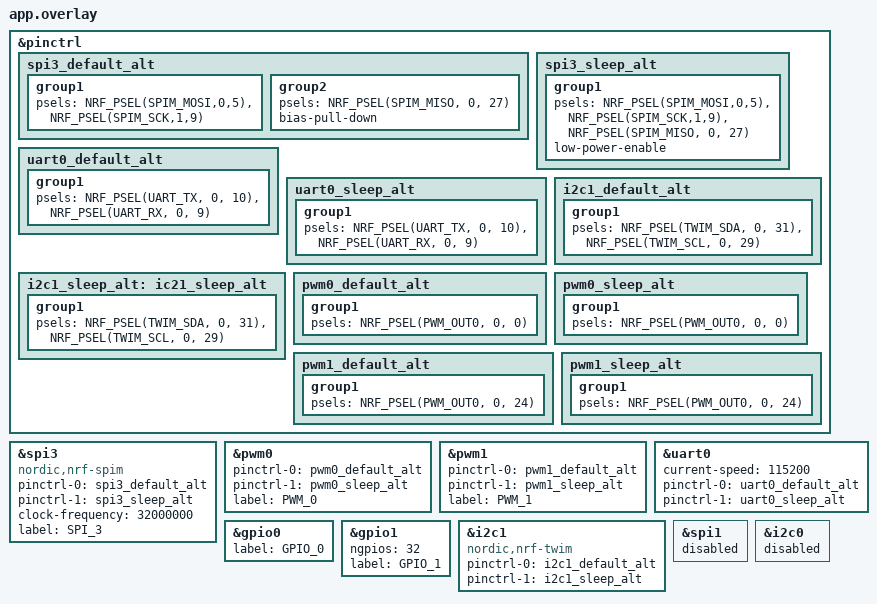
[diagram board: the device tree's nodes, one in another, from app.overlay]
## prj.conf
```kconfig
# Incresed stack due to settings API usage
CONFIG_SYSTEM_WORKQUEUE_STACK_SIZE=2048
CONFIG_MAIN_STACK_SIZE=4096


CONFIG_BT=y
CONFIG_BT_DEBUG_LOG=y
# Security manager protocol support for pairing
CONFIG_BT_SMP=y
# used to sign authenticated data
CONFIG_BT_SIGNING=y
# select peripheral role
CONFIG_BT_PERIPHERAL=n

# enable GATT device information service
CONFIG_BT_DIS=n
# number of buffers available for GATT writing
CONFIG_BT_ATT_PREPARE_COUNT=5


# enables local privacy feature support (Random MAC)
CONFIG_BT_PRIVACY=n
# name that appears when browsing
CONFIG_BT_DEVICE_NAME="DublinMaker"

# 0x4c0 = generic control device = 1216
CONFIG_BT_DEVICE_APPEARANCE=1216
# disable updating of device name to prevent use of generic name
# disable run-time changing of device name
CONFIG_BT_DEVICE_NAME_DYNAMIC=n
# CONFIG_BT_DEVICE_NAME_MAX=65
CONFIG_BT_OBSERVER=y
CONFIG_BT_KEYS_OVERWRITE_OLDEST=y

CONFIG_BT_RX_STACK_SIZE=1280
CONFIG_BT_CTLR_DUP_FILTER_LEN=0
CONFIG_BT_OBSERVER=y
CONFIG_BT_BROADCASTER=y
CONFIG_BT_PHY_UPDATE=n
CONFIG_BT_DATA_LEN_UPDATE=n

CONFIG_BT_MESH=y
CONFIG_BT_MESH_RELAY=y
CONFIG_BT_MESH_SEG_BUFS=10
CONFIG_BT_MESH_SUBNET_COUNT=1
CONFIG_BT_MESH_APP_KEY_COUNT=2
CONFIG_BT_MESH_MODEL_GROUP_COUNT=2
CONFIG_BT_MESH_ADV_BUF_COUNT=3
CONFIG_BT_MESH_LOOPBACK_BUFS=8
CONFIG_BT_MESH_PB_ADV=n
CONFIG_BT_MESH_CFG_CLI=y
CONFIG_BT_MESH_BEACON_ENABLED=n
CONFIG_BT_MESH_RPL_STORE_TIMEOUT=600
CONFIG_BT_MESH_DEBUG=y

CONFIG_BT_SETTINGS=n
CONFIG_FLASH=y
CONFIG_FLASH_PAGE_LAYOUT=y
CONFIG_FLASH_MAP=y
CONFIG_NVS=y
CONFIG_SETTINGS=y



# enable SPI and GPIO
CONFIG_SPI=y
CONFIG_SPI_NRFX=y
CONFIG_GPIO=y
CONFIG_PWM=y
# By default P0.10 and P0.9 are configured for NFC and so not available for GPIO/UART use.  
# This switches them back to GPIO
CONFIG_NFCT_PINS_AS_GPIOS=y
# This doesn't seem to be working
CONFIG_GPIO_AS_PINRESET=n

# enable uart driver
CONFIG_SERIAL=y

# enable console
CONFIG_CONSOLE=y
CONFIG_UART_CONSOLE=y
# Turn on internal RC clock
CONFIG_CLOCK_CONTROL_NRF_K32SRC_RC=y
CONFIG_I2C=y

CONFIG_PM=n
CONFIG_HEAP_MEM_POOL_SIZE=8192
#need to turn these off for microbit v2 as they prevent low level fiddling with the i2c devices
CONFIG_LIS2DH=n
CONFIG_LIS2MDL=n
```

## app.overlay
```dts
&pinctrl {
    /* IMPORTANT!  There should not be a space before the : in the next line (and similar below) */
    spi3_default_alt: spi3_default_alt {
        group1 {
            psels = <NRF_PSEL(SPIM_MOSI,0,5)>,
                    <NRF_PSEL(SPIM_SCK,1,9)>;
        };
        group2 {
        psels = <NRF_PSEL(SPIM_MISO, 0, 27)>;
        bias-pull-down;
        };
        
    };
    spi3_sleep_alt: spi3_sleep_alt {
        group1 {
            psels = <NRF_PSEL(SPIM_MOSI,0,5)>,
                    <NRF_PSEL(SPIM_SCK,1,9)>,
                    <NRF_PSEL(SPIM_MISO, 0, 27)>;
            low-power-enable;
        };
    };
    uart0_default_alt: uart0_default_alt {
        group1 {
            psels =  <NRF_PSEL(UART_TX, 0, 10)>,
                     <NRF_PSEL(UART_RX, 0, 9)>;
        };
    };
    uart0_sleep_alt: uart0_sleep_alt {
        group1 {
            psels =  <NRF_PSEL(UART_TX, 0, 10)>,
                     <NRF_PSEL(UART_RX, 0, 9)>;
        };
    };
    
    i2c1_default_alt: i2c1_default_alt {
        group1 {
            psels =  <NRF_PSEL(TWIM_SDA, 0, 31)>,
                     <NRF_PSEL(TWIM_SCL, 0, 29)>;
        };
    };
    i2c1_sleep_alt: ic21_sleep_alt {
        group1 {
            psels =  <NRF_PSEL(TWIM_SDA, 0, 31)>,
                     <NRF_PSEL(TWIM_SCL, 0, 29)>;
        };
    };

    pwm0_default_alt: pwm0_default_alt {
        group1 {
            psels =  <NRF_PSEL(PWM_OUT0, 0, 0)>;
        };
    };
    pwm0_sleep_alt: pwm0_sleep_alt {
        group1 {
            psels =  <NRF_PSEL(PWM_OUT0, 0, 0)>;
        };
    };
    
    pwm1_default_alt: pwm1_default_alt {
        group1 {
            psels =  <NRF_PSEL(PWM_OUT0, 0, 24)>;
        };
    };
    pwm1_sleep_alt: pwm1_sleep_alt {
        group1 {
            psels =  <NRF_PSEL(PWM_OUT0, 0, 24)>;
        };
    };    
    
};

&spi3 {
    compatible = "nordic,nrf-spim";
    status = "okay";
    // sck-pin = <41>; // P1.09
	// mosi-pin = <5>; // P0.05 
 /* Redirecting MISO to a pin that is not connected on the microbit v2 board */
	/* miso-pin = <27>; */
    pinctrl-0 = <&spi3_default_alt>;
    pinctrl-1 = <&spi3_sleep_alt>;
    pinctrl-names = "default", "sleep";
    clock-frequency = <32000000>;
    label = "SPI_3";
};
&pwm0 {
	status = "okay";
	//ch0-pin = <0>; 	
	pinctrl-0 = <&pwm0_default_alt>;
    pinctrl-1 = <&pwm0_sleep_alt>;
    pinctrl-names = "default", "sleep";
	label = "PWM_0";
	
};
&pwm1 {
	status = "okay";
	//ch0-pin = <24>;
	pinctrl-0 = <&pwm1_default_alt>;
    pinctrl-1 = <&pwm1_sleep_alt>;
    pinctrl-names = "default", "sleep";
	label = "PWM_1";
   
};
&uart0 {
        status = "okay";
        current-speed = <115200>;
    /*    tx-pin = <10>;
        rx-pin = <9>;
    */
    pinctrl-0 = <&uart0_default_alt>;
    pinctrl-1 = <&uart0_sleep_alt>;
    pinctrl-names = "default", "sleep";
};
&gpio0 {
	status = "okay";
	label="GPIO_0";
};
&gpio1 {
    status = "okay";
    ngpios = <32>;
	label="GPIO_1";
};
&i2c1 {
	compatible = "nordic,nrf-twim";
    status = "okay";
   // sda-pin = <31>; // P0.31 SDA on SAO connector
   // scl-pin = <29>; // P0.29 SCL on SAO connector
    pinctrl-0 = <&i2c1_default_alt>;
    pinctrl-1 = <&i2c1_sleep_alt>;
    pinctrl-names = "default", "sleep";
    
};
&spi1 {
    status = "disabled";
};
&i2c0 {
    status = "disabled";
};
```

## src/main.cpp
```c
#include <zephyr/zephyr.h>
#include <zephyr/sys/printk.h>

#include <zephyr/settings/settings.h>

#include <zephyr/bluetooth/bluetooth.h>
#include <zephyr/bluetooth/mesh.h>
#include <zephyr/bluetooth/hci.h>
#include <zephyr/bluetooth/conn.h>
#include <zephyr/bluetooth/uuid.h>
#include <zephyr/bluetooth/gatt.h>
#include <zephyr/drivers/pwm.h>
#include <zephyr/drivers/flash.h>
#include <zephyr/storage/flash_map.h>
#include <zephyr/fs/nvs.h>
//#include <stdlib.h>
#include "display.h"
#include "controller.h"
#include "console.h"
#include "sound.h"
#include "invaders.h"
#include "brici.h"
#include "mesh.h"
#include "battleship.h"
#include "messaging.h"
#include "frame_buffer.h"
#include "menu.h"
#include "osk.h"
#include "dmb_message_type.h"
#include "realm.h"
#include "logo_bricks.h"
extern console Console;

int doMainMenu()
{
	const char c1[]="Galaga";
	const char c2[]="Brici";
	const char c3[]="Battleship";
	const char c4[]="Microrealms";
    const char c5[]="Messaging";
	const char c6[]="Settings";
	const char c7[]="About";
	
	
	const char *choices[]={c1,c2,c3,c4,c5,c6,c7};
	menu Menu(&Console.Display, &Console.Controller, choices,sizeof(choices)/sizeof(const char *));
	Menu.show();	
	return Menu.getChoice(2000);
}

char Name[MAX_NAME_LEN];
uint16_t Address;

int load_settings(void);
int change_settings(void);
void drawLogo(uint32_t demo_mode);
void about(void);
int main(void)
{
	
	
	int ret;
	int count=0;		
	ret = Console.begin();		
    load_settings();
	mesh_begin(Address);
	if (ret < 0)
	{
		printk("\nError initializing console.  Error code = %d\n",ret);
		while(1);
	}
	
	uint16_t tones[]={A3,A5,E4,G4,A5};
	uint16_t times[]={150,150,150,150,250};
    Console.Sound.playMelody(tones, times,5);
	k_msleep(50);
	drawLogo(3);
	while(Console.Controller.getButtonState()==0);
    while(1) 
	{
		Console.Display.clear();
		ret = doMainMenu();
		printk("Choice=%d\r\n",ret);
		if (ret==0)
		{
			playInvaders(0);
		}
		if (ret == 1)
		{
			ClassicBrici();
		}
		if (ret == 2)
		{
			// Settings
			battleship();
		}
		if (ret == 3)
		{
			// Settings
			microrealms();
		}
		if (ret ==4 )
		{
			messaging();
		}
		if (ret == 5)
		{
			change_settings();
		}
		if (ret == 6)
		{
			about();
		}

		if (ret < 0) // timeout
			drawLogo(3);

	}
	playInvaders(1);
 	
	while(1)
	{
		//printk("Hello World! %s\n", CONFIG_BOARD);
       //Display.drawRectangle(random(0,119),random(0,119),random(0,120),random(0,120),random(0,0xffff));                                
       //Console.Display.fillRectangle(Console.random(0,240),Console.random(0,240),Console.random(0,240),Console.random(0,240),Console.random(0,0xffff));                   
		Console.Display.fillRectangle(0,0,SCREEN_WIDTH,SCREEN_HEIGHT,Console.random(0,0xffff));                   
		///Console.Display.fillRectangle(0,0,SCREEN_WIDTH,SCREEN_HEIGHT,0b1111111111111111);
		///k_msleep(100);
		//Console.Display.fillRectangle(0,0,SCREEN_WIDTH,SCREEN_HEIGHT,0b1111111111011111);                   
		//k_msleep(100);
       // display_drawCircle(random(0,240),random(0,240),random(0,135),random(0,0xffff));
        //Display.fillCircle(random(0,240),random(0,135),random(0,120),random(0,0xffff));

        count++;
        if (count >= 10) 
        {
      //      Console.Display.fillRectangle(0,0,SCREEN_WIDTH,SCREEN_HEIGHT,0);
			
		//	Console.Display.print("Starting over",sizeof("Starting over")-1,20,60,0xffff,0);
            count = 0;
		//	sendDMBMessage(msg_count++);

			//printk("restarting\n");
			if (Console.Controller.getButtonState())
			Console.Sound.playTone(1000,100);
			printk("Buttons = %x\n",Console.Controller.getButtonState());
			
 		//	printk("Buttons = %d\r\n",Console.Controller.getButtonState());
        }        
	}
	return 0;
}
static struct nvs_fs fs;
const struct device *flash_dev;

#define STORAGE_NODE DT_NODE_BY_FIXED_PARTITION_LABEL(storage)
#define FLASH_NODE DT_MTD_FROM_FIXED_PARTITION(STORAGE_NODE)
#define NAME_ID 1
#define ADDRESS_ID 2
int load_settings()
{
    int ret;
    struct flash_pages_info info;
    flash_dev = DEVICE_DT_GET(FLASH_NODE);
    if (!device_is_ready(flash_dev)) {
            printk("Flash device %s is not ready\n", flash_dev->name);
            return -1;
    }
    fs.offset = FLASH_AREA_OFFSET(storage);
    ret = flash_get_page_info_by_offs(flash_dev, fs.offset, &info);
    if (ret) {
            printk("Unable to get page info\n");
            return -2;
    }
    fs.sector_size = info.size;
    fs.sector_count = 2U;

    ret = nvs_init(&fs, flash_dev->name);
    if (ret) 
    {
        printk("Flash Init failed\n");
        return -3;
    }
    else
    {
        printk("Flash init success\n");
    }
    ret = nvs_read(&fs,NAME_ID,&Name,sizeof(Name));
    if (ret < 0)
    {
        Name[0]='D';
        Name[1]='U';
        Name[2]='B';
        Name[3]=0;
    }
    ret = nvs_read(&fs,ADDRESS_ID,&Address,sizeof(Address));
    if (ret < 0)
    {
        Address=1;
    }
    return 0;
    
}
int change_settings()
{
    int rc = 0;
	osk OSK;
	
    struct flash_pages_info info;

    flash_dev = DEVICE_DT_GET(FLASH_NODE);
    if (!device_is_ready(flash_dev)) {
            printk("Flash device %s is not ready\n", flash_dev->name);
            return -1;
    }
    fs.offset = FLASH_AREA_OFFSET(storage);
    rc = flash_get_page_info_by_offs(flash_dev, fs.offset, &info);
    if (rc) {
            printk("Unable to get page info\n");
            return -2;
    }
    fs.sector_size = info.size;
    fs.sector_count = 2U;

    rc = nvs_init(&fs, flash_dev->name);
    if (rc) 
    {
        printk("Flash Init failed\n");
        return -3;
    }
    else
    {
        printk("Flash init success\n");
    }
    rc = nvs_read(&fs,NAME_ID,&Name,sizeof(Name));
    Console.Display.clear();
    Console.Display.printX2("Badge name",10,0,0,Console.Display.RGBToWord(0xff,0xff,0), Console.Display.RGBToWord(0,0,0) );
    Console.Display.printX2(Name,Console.Display.mystrlen(Name),0,1+FONT_HEIGHT*2, Console.Display.RGBToWord(0xff,0xff,0), Console.Display.RGBToWord(0,0,0) );
    OSK.show(&Console.Display, &Console.Controller);
    if (OSK.getUserInput(Name)>0)
    {
        rc=nvs_write(&fs,NAME_ID,&Name,sizeof(Name));
    }
    Console.Display.clear();
    Console.Display.printX2("Badge name",10,0,0,Console.Display.RGBToWord(0xff,0xff,0), Console.Display.RGBToWord(0,0,0) );
    Console.Display.printX2(Name,Console.Display.mystrlen(Name),0,1+FONT_HEIGHT*2, Console.Display.RGBToWord(0xff,0xff,0), Console.Display.RGBToWord(0,0,0) );
    while(Console.Controller.getButtonState()); // wait for key release
    Console.Display.clear();
    int Done=0;
    Console.Display.printX2("Badge address",13,0,0,Console.Display.RGBToWord(0xff,0xff,0), Console.Display.RGBToWord(0,0,0) );
    while(!Done)
    {
        Console.Display.printX2(Address,0,1+FONT_HEIGHT*2, Console.Display.RGBToWord(0xff,0xff,0), Console.Display.RGBToWord(0,0,0) );
        uint16_t key=0;
        while(key == 0)
        {
            key=Console.Controller.getButtonState();
            k_msleep(50);
        }
        switch(key)
        {
            case Console.Controller.Up :
            {
                Address++;
                break;
            }
            case Console.Controller.Down :
            {
                Address--;
                break;
            }
            case Console.Controller.A :
            {
                Done=1;
                break;
            }
            case Console.Controller.B :
            {
                Done=2;
                break;
            }
        }
        k_msleep(50);
        if (Done == 1)
        {
            // new address entered
            rc=nvs_write(&fs,ADDRESS_ID,&Address,sizeof(Address));
        }
    }
    return 0;
}
void drawLogo(uint32_t demo_mode)
{
    brick Logo[LOGO_BRICK_COUNT];
    int Count;
    volatile int BrickDataIndex = 0;    
    uint16_t x,y,w,h;
    uint16_t r,g,b;
    uint16_t Colour;
    uint16_t Brick_Count = LOGO_BRICK_COUNT;
 // The logo is defined in the header file  logo_bricks.h
// The colours are defined in this file using just 2 bits for each colour component (r,g,b): total 6 bits of colour
// The following loop defines all of the bricks in memory and "expands" their colour definition to the 16 bits required by the display
    Console.Display.fillRectangle(0,0,SCREEN_WIDTH,SCREEN_HEIGHT,0);
    for (Count = 0; Count < LOGO_BRICK_COUNT; Count++)
    {        
        x = brickattribs[BrickDataIndex];
        y = brickattribs[BrickDataIndex + 1];
        w = brickattribs[BrickDataIndex + 2];
        h = brickattribs[BrickDataIndex + 3];
        Colour = brickattribs[BrickDataIndex + 4];
        r = (Colour & 0x30) >> 4;
        switch (r) {
            case 0: r=0;break;
            case 1: r=63;break;
            case 2: r=127;break;
            case 3: r=255;break;
        }
        g = (Colour & 0x0c) >> 2;
        switch (g) {
            case 0: g=0;break;
            case 1: g=63;break;
            case 2: g=127;break;
            case 3: g=255;break;
        }
        b = (Colour & 0x03);
        switch (b) {
            case 0: b=0;break;
            case 1: b=63;break;
            case 2: b=127;break;
            case 3: b=255;break;
        }
        Colour = COLOUR(r,g,b); // convert the 3 x 8 bit values to a single 16 bit value        
        Logo[Count].define(x,y,w,h,Colour);                           
        BrickDataIndex += 5;
        
    }   
    if (demo_mode == 0)
    {
        for (Count = 0; Count < LOGO_BRICK_COUNT; Count++)
        {
            Logo[Count].show();        
        }

    }
    if (demo_mode==1)
    {
        for (Count = 0; Count < LOGO_BRICK_COUNT; Count++)
        {
            Logo[Count].show();        
        }
        Brici(Logo,Brick_Count,SCREEN_WIDTH,1);
    }
    if (demo_mode==2)
    {
        sprite Invader = { DefaultInvaderImage, 3, 3, 10, 12};
        sprite AttackerMissile = { AttackerMissileImage, 0, 0, 5, 8  };
        Invader.show();
        Invader.move(Invader.getX()+Console.random(0,200),Invader.getY());
        int XDirectionChange = 0;
        int YDirectionChange = 0;
        int x_step = 2;
        int y_step = 1;
        for (Count = 0; Count < LOGO_BRICK_COUNT; Count++)
        {
            Logo[Count].move(Logo[Count].getX(),Logo[Count].getY()+120);
            Logo[Count].show();                    
        }
       
        for (Count = 0; Count < 4000; Count++)
        {
            if (Console.Controller.getButtonState()) // exit demo if the user presses a button
                return;
            XDirectionChange=0;
            YDirectionChange=0;
            Invader.move(Invader.getX() + x_step, Invader.getY() + y_step);
            if (Invader.getX() >= (SCREEN_WIDTH - Invader.getWidth()))
                XDirectionChange = 1;
            if (Invader.getX() == 0)
                XDirectionChange = 1;
            if (Invader.getY() > SCREEN_HEIGHT - 140)
            {
                YDirectionChange = 1;
                if (Invader.getY() < 3)
                {
                    YDirectionChange = 1;
                }
            }
            if (XDirectionChange) // Did an invader hit either edge?
                x_step = -x_step; // if so, then reverse direction
            if (YDirectionChange) // Did an invader hit either edge?
                y_step = -y_step; // if so, then reverse direction
            if (AttackerMissile.visible())
            {
                int16_t MissileTipX,MissileTipY;
                MissileTipX = AttackerMissile.getX()+AttackerMissile.getWidth() / 2;
                MissileTipY = AttackerMissile.getY()+AttackerMissile.getHeight() /2;
                for (int Index = 0; Index < LOGO_BRICK_COUNT; Index++)
                {
                    if (Logo[Index].visible())
                    {
                        if (Logo[Index].within(MissileTipX,MissileTipY))
                        {
                            Logo[Index].hide();
                            AttackerMissile.hide();
                           // Console.Sound.playTone(400,20);
                        }
                    }                                        
                }
                AttackerMissile.move(AttackerMissile.getX(),AttackerMissile.getY()+2);
                if (AttackerMissile.getY() > SCREEN_HEIGHT)
                    AttackerMissile.hide();
            }
            else
            {
                AttackerMissile.show();
                AttackerMissile.move(Invader.getX() + Invader.getWidth() / 2 - AttackerMissile.getWidth() / 2, Invader.getY() + AttackerMissile.getWidth() / 2);
            }
            k_msleep(10);
            
        }
    }
	if (demo_mode==3)
    { // Spire as a radio beacon
		for (Count = 0; Count < LOGO_BRICK_COUNT; Count++)
        {
			Logo[Count].move(Logo[Count].getX(),Logo[Count].getY()+60);
            Logo[Count].show();        
        }
		Console.Display.printX2("Address: ",9,0,SCREEN_HEIGHT - (6*FONT_HEIGHT),Console.Display.RGBToWord(0xff,0xff,0x03f),Console.Display.RGBToWord(0,0,0));		
		Console.Display.printX2(Address,10*FONT_WIDTH*2,SCREEN_HEIGHT - (6*FONT_HEIGHT),Console.Display.RGBToWord(0xff,0xff,0x03f),Console.Display.RGBToWord(0,0,0));
		DMBMessageReceived = 0;
		while(Console.Controller.getButtonState()==0)
		{
			Console.Display.putPixel(120,65,Console.Display.RGBToWord(0xff,0xff,0xff));
			Console.Display.putPixel(137,65,Console.Display.RGBToWord(0xff,0xff,0xff));
			Console.Display.putPixel(116,58,Console.Display.RGBToWord(0xff,0xff,0xff));
			Console.Display.putPixel(141,58,Console.Display.RGBToWord(0xff,0xff,0xff));
			Console.Display.putPixel(120,51,Console.Display.RGBToWord(0xff,0xff,0xff));
			Console.Display.putPixel(137,51,Console.Display.RGBToWord(0xff,0xff,0xff));
			Console.Display.putPixel(128,46,Console.Display.RGBToWord(0xff,0xff,0xff));
			Console.Display.putPixel(129,46,Console.Display.RGBToWord(0xff,0xff,0xff));
			k_msleep(100);
			Console.Display.putPixel(120,65,Console.Display.RGBToWord(0,0,0));
			Console.Display.putPixel(137,65,Console.Display.RGBToWord(0,0,0));
			Console.Display.putPixel(116,58,Console.Display.RGBToWord(0,0,0));
			Console.Display.putPixel(141,58,Console.Display.RGBToWord(0,0,0));
			Console.Display.putPixel(120,51,Console.Display.RGBToWord(0,0,0));
			Console.Display.putPixel(137,51,Console.Display.RGBToWord(0,0,0));
			Console.Display.putPixel(128,46,Console.Display.RGBToWord(0,0,0));
			Console.Display.putPixel(129,46,Console.Display.RGBToWord(0,0,0));
			k_msleep(100);
			if (DMBMessageReceived)
				messaging(DMBMessageSender);
		}
	}

}
void about()
{
	uint16_t row_pos = 0;
	Console.Display.clear();
	Console.Display.printX2("For software updates",sizeof("For software updates")-1,0,row_pos,Console.Display.RGBToWord(0xff,0xff,0xff),Console.Display.RGBToWord(0,0,0));
	row_pos += 2 + (FONT_HEIGHT*2);
	Console.Display.printX2("help with code",sizeof("help with code")-1,0,row_pos,Console.Display.RGBToWord(0xff,0xff,0xff),Console.Display.RGBToWord(0,0,0));
	row_pos += 2 + (FONT_HEIGHT*2);
	Console.Display.printX2("contact:",sizeof("contact:")-1,0,row_pos,Console.Display.RGBToWord(0xff,0xff,0xff),Console.Display.RGBToWord(0,0,0));
	row_pos += 2 + (FONT_HEIGHT*2);
	Console.Display.printX2("frank@ioprog.com",sizeof("frank@ioprog.com")-1,0,row_pos,Console.Display.RGBToWord(0xff,0xff,0xf),Console.Display.RGBToWord(0,0,0));
	while(Console.Controller.getButtonState()==0)
		k_msleep(50);
	while(Console.Controller.getButtonState()!=0)
		k_msleep(50);
}
```

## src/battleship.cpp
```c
#include <zephyr/zephyr.h>
#include <zephyr/sys/printk.h>
#include "mesh.h"
#include "display.h"
#include "console.h"
#include "controller.h"
#include "battleship.h"
#include "font5x7.h"
void ship::place(int len, int row, int col, int orientation)
{
    this->len = len;
    this->row = row;
    this->col = col;
    this->orientation = orientation;
    
    state = 0;
}
int ship::contains(int row, int col)
{
    // returns 1 if the ship occupies the square at this row, column
    // otherwise returns 0
    int return_value = 0;
    if (orientation == 0)
    {
        // Horizontal
        if (this->row == row) 
        {
            // same row.
            if ( (col >= this->col) && (col < (this->col+this->len)))
                return_value = 1; // it is within
        }
    }
    else
    {
        // Vertical
        if (this->col == col)
        {
            if ( (row >= this->row) && (row < (this->row+this->len)))
                return_value = 1; // it is within
        }
    }
    return return_value; // not within the bounds of this ship
}
int ship::overlaps(int len, int row, int col, int orientation)
{
    // returns 1 if the ship described by the parameters overlaps
    // this ship - uses for initial ship placement.
    // otherwise returns 0
    int return_value = 0;
    if (orientation == 0)
    {
        // Horizontal
        for (int count = 0; count < len; count++)
        {
            if (this->contains(row,col+count))
                return_value = 1;
        }
    }
    else
    {
        // Vertical
        for (int count = 0; count < len; count++)
        {
            if (this->contains(row+count,col))
                return_value = 1;
        }
    }
    return return_value;
}
/* each square can have the following properties:
 * Empty
 * Your ship (ship_id with particular bit pattern for you/them)
 * Their ship
 * Your ship hit
 * Their ship hit
 * uint8_t my_ship_map[10][10];
 */

void battleship()
{
    int row,col;
    uint8_t map[10][10];
    int ship_counter = 0;
    int Done=0;
    uint16_t target=0;
    int my_ship_hit_counter = 0;
    int their_ship_hit_counter = 0;
    int total_hits;
    total_hits = (CARRIER_COUNT*CARRIER_SQUARES) + (BATTLESHIP_COUNT*BATTLESHIP_SQUARES)+(SUBMARINE_COUNT*SUBMARINE_SQUARES)+(PATROL_BOAT_COUNT*PATROL_BOAT_SQUARES); 
	mesh_clearReplay();

    Console.Display.clear();
    Console.Display.printX2("Target node: ", 13,0,0,Console.Display.RGBToWord(0xff,0xff,0), Console.Display.RGBToWord(0,0,0) );
    while(!Done)
    {
        Console.Display.printX2(target,0,1+FONT_HEIGHT*2, Console.Display.RGBToWord(0xff,0xff,0), Console.Display.RGBToWord(0,0,0) );
        uint16_t key=0;
        while(key == 0)
        {
            key=Console.Controller.getButtonState();
            k_msleep(50);
        }
        switch(key)
        {
            case Console.Controller.Up :
            {
                target++;
                break;
            }
            case Console.Controller.Down :
            {
                target--;
                break;
            }
            case Console.Controller.A :
            {
                Done=1;
                break;
            }
            case Console.Controller.B :
            {
                Done=2;
                break;
            }
        }
        k_msleep(100);
    }

    ship Ships[CARRIER_COUNT+BATTLESHIP_COUNT+SUBMARINE_COUNT+PATROL_BOAT_COUNT];
    Console.Display.clear();
    
    for (row=0;row<10;row++)
    {
        Console.Display.drawLine(0,row*(SCREEN_HEIGHT/10),SCREEN_WIDTH,row*(SCREEN_HEIGHT/10),Console.Display.RGBToWord(0xf,0xf,0xff));
    }
    for (col=0;col<10;col++)
    {
        Console.Display.drawLine(col*(SCREEN_WIDTH/10),0,col*(SCREEN_WIDTH/10),SCREEN_HEIGHT,Console.Display.RGBToWord(0xf,0xf,0xff));
    }
    Console.Display.drawLine(0,SCREEN_HEIGHT-1,SCREEN_WIDTH-1,SCREEN_HEIGHT-1,Console.Display.RGBToWord(0xf,0xf,0xff));
    Console.Display.drawLine(SCREEN_WIDTH-1,0,SCREEN_WIDTH-1,SCREEN_HEIGHT-1,Console.Display.RGBToWord(0xf,0xf,0xff));
    for (row=0;row<10;row++)
    {
        for (col=0;col<10;col++)
            map[row][col]=0;
    }
    // start placing ships
    // Aircraft carrier first as it will be hardest to position.
    int orientation = Console.random(0,2);
    if (orientation == 0)
    {
        // Horizontal
        col=Console.random(0,CARRIER_SQUARES);
        row=Console.random(0,10);
        for (int i=0;i<CARRIER_SQUARES;i++)
            map[row][col+i]=MY_SHIP_NORMAL;
    }
    else
    {        
        col=Console.random(0,10);
        row=Console.random(0,CARRIER_SQUARES);
        for (int i=0;i<CARRIER_SQUARES;i++)
            map[row+i][col]=MY_SHIP_NORMAL;
    }
    Ships[ship_counter].place(CARRIER_SQUARES,row,col,orientation);
    ship_counter++;
    
    // Place Battleships
    int len = BATTLESHIP_SQUARES;    
    for (int ship_class_count = 0; ship_class_count < BATTLESHIP_COUNT; ship_class_count++)
    {
        Done = 0;    
        while( !Done )
        {
            // Attempt to get an empty part of the board;
            orientation = Console.random(0,2);
            if (orientation == 0)
            {
                // Horizontal
                col=Console.random(0,len);
                row=Console.random(0,10);
            }
            else
            {        
                col=Console.random(0,10);
                row=Console.random(0,len);
            }
            int invalid = 0;
            for (int ship_index=0; ship_index < ship_counter; ship_index++)
            {
                if (Ships[ship_index].overlaps(len,row,col,orientation))
                    invalid = 1;
                
            }
            if (invalid == 0)
                Done = 1;
        }
        if (orientation == 0)
        {
            for (int i=0;i<len;i++)
                map[row][col+i]=MY_SHIP_NORMAL;
        }
        else
        {
            for (int i=0;i<len;i++)
                map[row+i][col]=MY_SHIP_NORMAL;
        }
        Ships[ship_counter].place(BATTLESHIP_SQUARES,row,col,orientation);
        ship_counter++;
    }
    
    // Place submarines
    len = SUBMARINE_SQUARES;
    for (int ship_class_count = 0; ship_class_count < SUBMARINE_COUNT; ship_class_count++)
    {
        Done = 0;    
        while( !Done )
        {
            // Attempt to get an empty part of the board;
            orientation = Console.random(0,2);
            if (orientation == 0)
            {
                // Horizontal
                col=Console.random(0,len);
                row=Console.random(0,10);
            }
            else
            {        
                col=Console.random(0,10);
                row=Console.random(0,len);
            }
            int invalid = 0;
            for (int ship_index=0; ship_index < ship_counter; ship_index++)
            {
                if (Ships[ship_index].overlaps(len,row,col,orientation))
                    invalid = 1;
                
            }
            if (invalid == 0)
                Done = 1;
        }
        if (orientation == 0)
        {
            for (int i=0;i<len;i++)
                map[row][col+i]=MY_SHIP_NORMAL;
        }
        else
        {
            for (int i=0;i<len;i++)
                map[row+i][col]=MY_SHIP_NORMAL;
        }
        Ships[ship_counter].place(SUBMARINE_SQUARES,row,col,orientation);
        ship_counter++;
    }

    // Place Patrol boats
    len = PATROL_BOAT_SQUARES;    
    for (int ship_class_count = 0; ship_class_count < PATROL_BOAT_COUNT; ship_class_count++)
    {
        Done = 0;    
        while( !Done )
        {
            // Attempt to get an empty part of the board;
            orientation = Console.random(0,2);
            if (orientation == 0)
            {
                // Horizontal
                col=Console.random(0,len);
                row=Console.random(0,10);
            }
            else
            {        
                col=Console.random(0,10);
                row=Console.random(0,len);
            }
            int invalid = 0;
            for (int ship_index=0; ship_index < ship_counter; ship_index++)
            {
                if (Ships[ship_index].overlaps(len,row,col,orientation))
                    invalid = 1;
                
            }
            if (invalid == 0)
                Done = 1;
        }
        if (orientation == 0)
        {
            for (int i=0;i<len;i++)
                map[row][col+i]=MY_SHIP_NORMAL;
        }
        else
        {
            for (int i=0;i<len;i++)
                map[row+i][col]=MY_SHIP_NORMAL;
        }
        Ships[ship_counter].place(PATROL_BOAT_SQUARES,row,col,orientation);
        ship_counter++;
    }
    
    
    
    uint16_t x,y,old_row,old_col;
    x=y=old_row=old_col=0;
    Done = 0;
    while(!Done)
    {
        
        // Hide the old dot
        x = old_col * (SCREEN_WIDTH/10)+SCREEN_WIDTH/20;
        y = old_row * (SCREEN_WIDTH/10)+SCREEN_WIDTH/20;
        Console.Display.fillCircle(x,y,8,Console.Display.RGBToWord(0,0,0));
        for (int map_row=0;map_row<10;map_row++)
        {
            for (int map_col=0;map_col < 10; map_col++)
            {
                if (map[map_row][map_col]==MY_SHIP_NORMAL)
                {
                    Console.Display.fillRectangle(map_col*(SCREEN_WIDTH/10),map_row*(SCREEN_HEIGHT/10),SCREEN_WIDTH/10,SCREEN_HEIGHT/10,Console.Display.RGBToWord(0xff,0xff,0xff));
                }
                else if (map[map_row][map_col]==MY_SHIP_HIT)
                {
                    Console.Display.fillRectangle(map_col*(SCREEN_WIDTH/10),map_row*(SCREEN_HEIGHT/10),SCREEN_WIDTH/10,SCREEN_HEIGHT/10,Console.Display.RGBToWord(0xff,0xf,0xf));
                }
                else if (map[map_row][map_col]==THEIR_SHIP_NORMAL)
                {
                    Console.Display.fillRectangle(map_col*(SCREEN_WIDTH/10),map_row*(SCREEN_HEIGHT/10),SCREEN_WIDTH/10,SCREEN_HEIGHT/10,Console.Display.RGBToWord(0x0,0xff,0xff));                    
                }
                else if (map[map_row][map_col]==THEIR_SHIP_HIT)
                {
                    Console.Display.fillRectangle(map_col*(SCREEN_WIDTH/10),map_row*(SCREEN_HEIGHT/10),SCREEN_WIDTH/10,SCREEN_HEIGHT/10,Console.Display.RGBToWord(0xff,0x0,0xff));                    
                }
            }
        }        
        // show the new dot        
        x = col * (SCREEN_WIDTH/10)+SCREEN_WIDTH/20;
        y = row * (SCREEN_WIDTH/10)+SCREEN_WIDTH/20;
        Console.Display.fillCircle(x,y,8,Console.Display.RGBToWord(0x1f,0x1f,0xff));
        old_row = row;
        old_col = col;
        uint16_t key=0;
        while(key == 0)
        {
            key=Console.Controller.getButtonState();
            if (DMBGameMessageReceived)
            {
                // incoming message from the other player.
                uint16_t target_row, target_col, hit;
                DMBGameMessageReceived = 0;
                hit = 0;
                target_row=DMBGameMailBox.Message[0];
                target_col=DMBGameMailBox.Message[1];
                printk("Target %d, %d \n",target_row,target_col);
                for (int ship_counter = 0; ship_counter < (CARRIER_COUNT+BATTLESHIP_COUNT+SUBMARINE_COUNT+PATROL_BOAT_COUNT); ship_counter++)
                {
                    if (Ships[ship_counter].contains(target_row,target_col))  
                    {
                        hit = 1;
                        if (map[target_row][target_col] != MY_SHIP_HIT)
                        {
                            my_ship_hit_counter++;
                        }
                        if (my_ship_hit_counter >= total_hits)
                        {
                            Console.Display.clear();
                            Console.Display.printX2("You lose!",9,5,20,Console.Display.RGBToWord(0xff,0xf,0xf),Console.Display.RGBToWord(0,0,0));
							Done=1;
                        }
                        map[target_row][target_col]=MY_SHIP_HIT;
                        // Fill in the square with the MY_SHIP_HIT colour  
                        Console.Display.fillRectangle(target_col*(SCREEN_WIDTH/10),target_row*(SCREEN_HEIGHT/10),SCREEN_WIDTH/10,SCREEN_HEIGHT/10,Console.Display.RGBToWord(0xff,0xf,0xf));
                    }
                }
                dmb_message response;
                response.Message[0]=hit;
                
                sendDMBGameResponseMessage(target,&response);
            }
            k_msleep(50);
        }
        
        switch(key)
        {
            case Console.Controller.Up :
            {
                row--;
                break;
            }
            case Console.Controller.Down :
            {
                row++;
                break;
            }
            case Console.Controller.Left :
            {
                col--;
                break;
            }
            case Console.Controller.Right :
            {
                col++;
                break;
            }
            case Console.Controller.A :
            {
                // Send a message to the opponent with row/col and wait for a reply (with timeout)
                DMBGameMessageResponseReceived = 0;
                dmb_message msg;
                msg.Message[0]=row;
                msg.Message[1]=col;
                sendDMBGameMessage(target,&msg);
                // wait for a reply
                uint32_t Timeout=100;
                while( (!DMBGameMessageResponseReceived) && (Timeout--))
                    k_msleep(10);
                if (DMBGameMessageResponseReceived)
                {                    
                    if (DMBGameResponseMailBox.Message[0]==1) 
                    {
                        // It's a hit 
                        if (map[row][col] != THEIR_SHIP_HIT)
                        {
                            their_ship_hit_counter++;
                        }
                        if (their_ship_hit_counter >= total_hits)
                        {
                            Console.Display.clear();
                            Console.Display.printX2("You win!",8,5,20,Console.Display.RGBToWord(0xff,0xff,0),Console.Display.RGBToWord(0,0,0));
							while(Console.Controller.getButtonState()==0)
								k_msleep(50);
							return;
							
                        }
                        map[row][col]=THEIR_SHIP_HIT;
                        Console.Display.fillRectangle(col*(SCREEN_WIDTH/10),row*(SCREEN_HEIGHT/10),SCREEN_WIDTH/10,SCREEN_HEIGHT/10,Console.Display.RGBToWord(0xff,0x0,0xff));     
                    }
                    else
                    {
                       // if (map[row][col] != 0)
                        {
                            map[row][col]=THEIR_SHIP_NORMAL;
                        }
                    }
                }
                else 
                {
                    printk("Message response timeout\n");
                }
                break;
            }
        }
        k_msleep(50);
        if (row < 0)
            row=0;
        if (col < 0)
            col = 0;
        if (row > 9)
            row=9;
        if (col > 9)
            col=9;
       
    }
    while(Console.Controller.getButtonState()==0)
	{
		k_msleep(50);
	}
	return;
    
}
```

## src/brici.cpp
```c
#include <stdint.h>
#include "console.h"

#include "sprite.h"
#include "brick.h"
#include "brici.h"
#define DEMO_HITS 10
void ClassicBrici()
{   
    #define Brick_Width 30
    #define Brick_Height 10
    #define BRICK_COUNT ( (3*SCREEN_WIDTH) / Brick_Width )
    Console.Display.fillRectangle(0,0,SCREEN_WIDTH-1,SCREEN_HEIGHT-1,0);
    brick Bricks[BRICK_COUNT];
    uint16_t RowCount=0;
    uint32_t Brick_Count = BRICK_COUNT;
    uint32_t Index=0;
    uint16_t x,y,w,h;
    uint16_t r,g,b;
    uint16_t Colour;
    for (Index=0;Index < Brick_Count/3; Index++)
    {
        r=255;
        b=64;
        g=255;
        x=RowCount*Brick_Width;
        y=50;
        Bricks[Index].define(x,y,Brick_Width,Brick_Height,Console.Display.RGBToWord(r,g,b));
        RowCount++;
    }
    RowCount = 0;
    for (Index=Brick_Count/3;Index < (2*Brick_Count)/3; Index++)
    {
        r=64;
        b=64;
        g=255;
        x=RowCount*Brick_Width;
        y=50+Brick_Height;
        Bricks[Index].define(x,y,Brick_Width,Brick_Height,Console.Display.RGBToWord(r,g,b));
        RowCount++;
    }
    RowCount = 0;
    for (Index=(2*Brick_Count)/3;Index < Brick_Count; Index++)
    {
        r=64;
        b=255;
        g=64;
        x=RowCount*Brick_Width;
        y=50+2*Brick_Height;
        Bricks[Index].define(x,y,Brick_Width,Brick_Height,Console.Display.RGBToWord(r,g,b));
        RowCount++;
    }
    Brici(Bricks,Brick_Count,30,0);
}
void Brici(brick *Bricks, uint16_t Brick_Count, uint16_t BatWidth,uint16_t demo_mode)
{
    
    
    brick Bat(0, SCREEN_HEIGHT-20, BatWidth, 3,Console.Display.RGBToWord(255,255,255));    
    brick Ball(SCREEN_WIDTH/2, SCREEN_HEIGHT/2, 3, 3,Console.Display.RGBToWord(255,255,255));
#define MAX_BRICI_LEVELS 4
    int Level = MAX_BRICI_LEVELS;
    int LevelComplete = 0;
    int8_t BallCount = 5;
    uint8_t Index;
    int8_t BallXVelocity = 1;
    int8_t BallYVelocity = 1;   
    uint32_t BatHits=0;

    while (Level > 0)
    {
        for (Index = 0; Index < Brick_Count; Index++)
        {
            Bricks[Index].show();
            if (!demo_mode)
                Console.Display.drawRectangle(Bricks[Index].getX(),Bricks[Index].getY(),Bricks[Index].getWidth(),Bricks[Index].getHeight(),0);
        }
        Ball.move(Console.random(10, SCREEN_WIDTH-10), SCREEN_HEIGHT/2);
        if (Console.random(0,2) > 0)
            BallXVelocity = 1;
        else
            BallXVelocity = -1;
        LevelComplete = 0;
        BallYVelocity = -1;        
        for (Index = BallCount; Index > 0; Index--)
            Console.Display.fillRectangle(SCREEN_WIDTH - Index * 15, SCREEN_HEIGHT-10, 10, 10, Console.Display.RGBToWord(0xff, 0xf, 0xf));        
        Ball.show();
        Bat.show();
        Console.Display.print("Level", 5, 5, SCREEN_HEIGHT-10, Console.Display.RGBToWord(0xff, 0xff, 0xff), Console.Display.RGBToWord(0, 0, 0));
        Console.Display.print(MAX_BRICI_LEVELS - Level + 1, 60, SCREEN_HEIGHT-10, Console.Display.RGBToWord(0xff, 0xff, 0xff), Console.Display.RGBToWord(0, 0, 0));
        
        while (!LevelComplete)
        {            
            if (Console.Controller.getButtonState() & Console.Controller.Right)
            {
                // Move right
                if (Bat.getX() < (SCREEN_WIDTH - Bat.getWidth()))
                {
                    Bat.move(Bat.getX() + 2, Bat.getY()); // Move the bat faster than the ball
                }
            }
            
            if (Console.Controller.getButtonState() & Console.Controller.Left)
            {
                // Move left
                if (Bat.getX() > 0)
                {
                    Bat.move(Bat.getX() - 2, Bat.getY()); // Move the bat faster than the ball
                }
            }
            
            if (Bat.touching(Ball.getX() + Ball.getWidth() / 2, Ball.getY() + Ball.getHeight() / 2))
            { // Ball bounced off the bat
                BallYVelocity = -BallYVelocity; 
                if (!demo_mode)
                    Console.Sound.playTone(200,20);
                if (demo_mode) 
                {
                    if (Console.Controller.getButtonState())
                    {
                        // Someone pushed a button - get out of demo mode
                        return;
                    }
                    BatHits++;                
                    if (BatHits >= DEMO_HITS)
                    {
                       return;      
                    }
                }
            }                        
            Ball.move(Ball.getX() + BallXVelocity, Ball.getY() + BallYVelocity); // update ball position
            if (Ball.getX() == 2) // bounced off left side?
            {
                BallXVelocity = -BallXVelocity;
                if (!demo_mode)
                    Console.Sound.playTone(400,20);
            }
            if (Ball.getX() == SCREEN_WIDTH - 2) // bounced off right side?
            {
                BallXVelocity = -BallXVelocity;
                if (!demo_mode)
                    Console.Sound.playTone(400,20);
            }
            if (Ball.getY() == 2)  // bounced off top? (behind the block)
            {
                BallYVelocity = -BallYVelocity;
                if (!demo_mode)
                    Console.Sound.playTone(400,20);
            }
            
            if (Ball.getY() >= Bat.getY() + Bat.getHeight() + 2)  // Did the ball go behind the bat?
            {
                BallCount--;  // Lost a ball!
                if (BallCount == 0) // Any left?
                {
                    // Nope: hard luck, game over
                    Console.Display.fillRectangle(0, 0, SCREEN_WIDTH, SCREEN_HEIGHT, 0);
                    Console.Display.print("GAME OVER", 9, 80, 100, Console.Display.RGBToWord(0xff, 0xff, 0xff), 0);
                    Console.Display.print("Press A to restart", 15, 60, 120, Console.Display.RGBToWord(0xff, 0xff, 0), Console.Display.RGBToWord(0, 0, 0));
                    while (!(Console.Controller.getButtonState() & Console.Controller.A))
                        k_msleep(10);
                    return;
                }
                // start a new ball moving in a random way
                if (Console.random(0,100) & 1)
                    BallXVelocity = 1;
                else
                    BallXVelocity = -1;
                BallYVelocity = -1;
                Ball.move(Console.random(10, SCREEN_WIDTH - 10), Console.random(90, 120));
                Console.Display.fillRectangle(SCREEN_WIDTH-5*15, SCREEN_HEIGHT-10, 120, 10, 0);  // wipe out the remaining lives area
                for (Index = BallCount; Index > 0; Index--) //  draw remaining lives
                    Console.Display.fillRectangle(SCREEN_WIDTH - Index * 15, SCREEN_HEIGHT-10, 10, 10, Console.Display.RGBToWord(0xff, 0xf, 0xf));
                
            }
            LevelComplete = 1;
            // Check to see if the ball has hit any of the blocks
            for (Index = 0; Index < Brick_Count; Index++)
            {
                if (Bricks[Index].visible()) // any blocks left?
                    LevelComplete = 0; // If yes then the level is not complete
                    
                int touch = 0;
                // Check all 4 corners of the ball for touching
                touch += Bricks[Index].touching(Ball.getX(), Ball.getY());
                if (touch == 0)
                    touch = Bricks[Index].touching(Ball.getX()+2, Ball.getY());
                if (touch == 0)
                    touch = Bricks[Index].touching(Ball.getX(), Ball.getY()+2);
                if (touch == 0)
                    touch = Bricks[Index].touching(Ball.getX()+2, Ball.getY()+2);
                if (touch)
                { // Block hit so hide it.
                    Bricks[Index].hide();  
                    if ( (touch == 1) || (touch == 3) )
                        BallYVelocity = -BallYVelocity;
                    if ( (touch == 2) || (touch == 4) )
                        BallXVelocity = -BallXVelocity;
                    if (!demo_mode)
                        Console.Sound.playTone(1000,20);
                }
            }
            // No Blocks left, Move to next level.
            if ((LevelComplete == 1) && (Level > 0))
            {
                Level--;
                Ball.hide();
                Console.Display.print("Level", 5, 5, SCREEN_HEIGHT-10, Console.Display.RGBToWord(0xff, 0xff, 0xff), Console.Display.RGBToWord(0, 0, 0));
                Console.Display.print(MAX_BRICI_LEVELS - Level + 1, 60, SCREEN_HEIGHT-10, Console.Display.RGBToWord(0xff, 0xff, 0xff), Console.Display.RGBToWord(0, 0, 0));                
            }
            if (!demo_mode)
            {
                k_msleep(Level+5); // Slow the game to human speed                
            }
            else
            {
                k_msleep(5); // Slow the game to human speed                
            }
            Bat.redraw(); // redraw bat as it might have lost a pixel due to collisions          
        }
    }
}
```

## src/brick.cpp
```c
#include <stdint.h>
#include "console.h"
#include "sprite.h"
#include "brick.h"

brick::brick( uint16_t x, uint16_t y, uint16_t w, uint16_t h,  uint16_t fillcolour)
{
    
    this->Visible = 0;        
    define(x,y,w,h,fillcolour);
}
brick::brick()
{
    this->Visible = 0;
}

void brick::define( uint16_t x, uint16_t y, uint16_t w, uint16_t h,uint16_t fillcolour)
{       
    this->fillcolour = fillcolour;
    this->Visible = 0;    
    this->w = w;
    this->h = h;
    this->X = x;
    this->Y = y;    
}

void brick::show()
{
    //if (!Visible)
    {                
        Console.Display.fillRectangle(X,Y,w,h,fillcolour);           
    }
    Visible=1;
    
}

void brick::hide()
{
    if (Visible)
    {
        // assumes a black backgound (colour = 0)
        Console.Display.fillRectangle(X,Y,w,h,0);
    }
    Visible = 0;
}
```

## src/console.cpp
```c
#include <zephyr/random/rand32.h>
#include "console.h"
#include "font5x7.h"
console Console;
int console::begin()
{    
    Display.begin();    
    Controller.begin();
    Sound.begin();
    random_seed();
    return 0;
}

uint32_t console::random(uint32_t lower,uint32_t upper)
{
    return (prbs()%(upper-lower))+lower;
}
uint32_t console::prbs()
{
	// This is an unverified 31 bit PRBS generator
	// It should be maximum length but this has not been verified 
	unsigned long new_bit=0;
	static int busy=0; // need to prevent re-entrancy here
	if (!busy)
	{
		busy=1;
		new_bit= ((shift_register & (1<<27))>>27) ^ ((shift_register & (1<<30))>>30);
		new_bit= ~new_bit;
		new_bit = new_bit & 1;
		shift_register=shift_register << 1;
		shift_register=shift_register | (new_bit);
		busy=0;
	}
	return shift_register & 0x7fffffff; // return 31 LSB's 
}
void console::random_seed()
{
    // Need to find a source of random data.  This layer of BBG is meant to be 
    // hardware independent so I don't want to break that.  Will have to obtain 
    // a random seed from one of the lower layers of the BBG stack without introducing
    // additional complexity.  Hardware aware object choices: Controller, Display, Timer, Sound
    // An analogue input would be nice so this probably rules out the Display and Timer objects
    // leaving Sound and Controller.  Some variations of BBG may use an analogue joystick so 
    // perhaps a call to readAnalogue(chan_num) might be a good choice?  The channel number
    // can be defined in the controller class (as a static) and mapped appropriately within the
    // Controller object.  Will add up and scale a few reads to change more bits in the shift register
    shift_register = 0;
    while(shift_register ==0)
    {
        shift_register = sys_rand32_get();
    }
	return;
    while(shift_register == 0)
    {
        for (int i=1;i<17;i++)
            shift_register += Controller.readTemperature()<<i;
    }   
    Controller.stopADC();
}
void console::sleep(uint32_t ms)
{
	k_msleep(ms);
}
```

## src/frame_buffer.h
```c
#ifndef __FRAME_BUFFER
#define __FRAME_BUFFER
#include <stdint.h>
#define TILE_WIDTH 30
#define TILE_HEIGHT 30
#define FRAMEBUFFER_WIDTH (2*TILE_WIDTH)
#define FRAMEBUFFER_HEIGHT (2*TILE_HEIGHT)
// A pixel with the value below is NOT drawn.  This enables transparency
#define TRANSPARENT_VALUE (0xffff)
class frame_buffer 
{
public:
	void openAperture(uint16_t x, uint16_t y, uint16_t w, uint16_t h);
	void put(uint16_t value);
	void fillRectangle(uint16_t x, uint16_t y, uint16_t w, uint16_t h,uint16_t c);
	void putImage(uint16_t x, uint16_t y, uint16_t w, uint16_t h,uint16_t *pImage);
	uint16_t Frame_Buffer[FRAMEBUFFER_WIDTH*FRAMEBUFFER_HEIGHT];
	
private:
	uint16_t fb_ap_tlx,fb_ap_tly,fb_ap_w,fb_ap_h,fb_x,fb_y;
	
};
#endif
```
